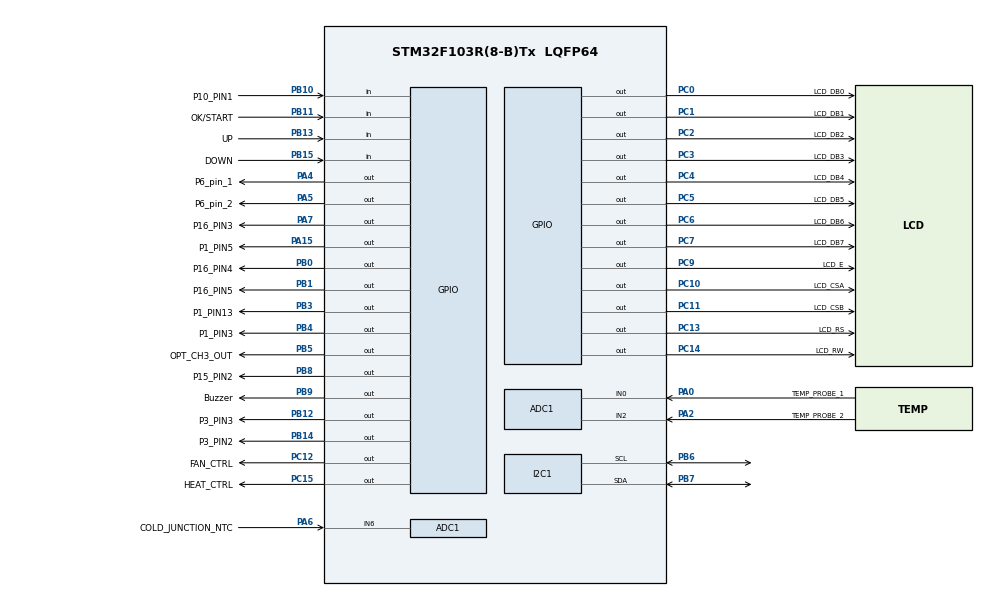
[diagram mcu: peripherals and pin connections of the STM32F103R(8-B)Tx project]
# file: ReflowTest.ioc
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ADC1.Channel-0\#ChannelRegularConversion=ADC_CHANNEL_6
ADC1.NbrOfConversionFlag=1
ADC1.Rank-0\#ChannelRegularConversion=1
ADC1.SamplingTime-0\#ChannelRegularConversion=ADC_SAMPLETIME_1CYCLE_5
ADC1.master=1
Mcu.Family=STM32F1
Mcu.Name=STM32F103R(8-B)Tx
Mcu.Package=LQFP64
NVIC.PriorityGroup=NVIC_PRIORITYGROUP_4
PA0-WKUP.GPIO_Label=TEMP_PROBE_1
PA0-WKUP.Signal=ADCx_IN0
PA10.Signal=USART1_RX
PA13.Mode=Serial_Wire
PA13.Signal=SYS_JTMS-SWDIO
PA14.Mode=Serial_Wire
PA14.Signal=SYS_JTCK-SWCLK
PA15.GPIO_Label=P1_PIN5
PA15.Signal=GPIO_Output
PA2.GPIO_Label=TEMP_PROBE_2
PA2.Signal=ADCx_IN2
PA4.GPIO_Label=P6_pin_1
PA4.Signal=GPIO_Output
PA5.GPIO_Label=P6_pin_2
PA5.Signal=GPIO_Output
PA6.GPIO_Label=COLD_JUNCTION_NTC
PA6.Signal=ADCx_IN6
PA7.GPIO_Label=P16_PIN3
PA7.Signal=GPIO_Output
PA9.Signal=USART1_TX
PB0.GPIO_Label=P16_PIN4
PB0.Signal=GPIO_Output
PB1.GPIO_Label=P16_PIN5
PB1.Signal=GPIO_Output
PB10.GPIO_Label=P10_PIN1
PB10.Signal=GPIO_Input
PB11.GPIO_Label=OK/START
PB11.GPIO_PuPd=GPIO_PULLUP
PB11.Signal=GPIO_Input
PB12.GPIO_Label=P3_PIN3
PB12.Signal=GPIO_Output
PB13.GPIO_Label=UP
PB13.GPIO_PuPd=GPIO_PULLUP
PB13.Signal=GPIO_Input
PB14.GPIO_Label=P3_PIN2
PB14.Signal=GPIO_Output
PB15.GPIO_Label=DOWN
PB15.GPIO_PuPd=GPIO_PULLUP
PB15.Signal=GPIO_Input
PB3.GPIO_Label=P1_PIN13
PB3.Signal=GPIO_Output
PB4.GPIO_Label=P1_PIN3
PB4.Signal=GPIO_Output
PB5.GPIO_Label=OPT_CH3_OUT
PB5.Signal=GPIO_Output
PB6.Mode=I2C
PB6.Signal=I2C1_SCL
PB7.Mode=I2C
PB7.Signal=I2C1_SDA
PB8.GPIO_Label=P15_PIN2
PB8.Signal=GPIO_Output
PB9.GPIO_Label=Buzzer
PB9.Signal=GPIO_Output
PC0.GPIO_Label=LCD_DB0
PC0.Signal=GPIO_Output
PC1.GPIO_Label=LCD_DB1
PC1.Signal=GPIO_Output
PC10.GPIO_Label=LCD_CSA
PC10.Signal=GPIO_Output
PC11.GPIO_Label=LCD_CSB
PC11.Signal=GPIO_Output
PC12.GPIO_Label=FAN_CTRL
PC12.GPIO_PuPd=GPIO_PULLDOWN
PC12.Signal=GPIO_Output
PC13-TAMPER-RTC.GPIO_Label=LCD_RS
PC13-TAMPER-RTC.Signal=GPIO_Output
PC14-OSC32_IN.GPIO_Label=LCD_RW
PC14-OSC32_IN.GPIO_PuPd=GPIO_PULLDOWN
PC14-OSC32_IN.Signal=GPIO_Output
PC15-OSC32_OUT.GPIO_Label=HEAT_CTRL
PC15-OSC32_OUT.GPIO_PuPd=GPIO_PULLDOWN
PC15-OSC32_OUT.Signal=GPIO_Output
PC2.GPIO_Label=LCD_DB2
PC2.Signal=GPIO_Output
PC3.GPIO_Label=LCD_DB3
PC3.Signal=GPIO_Output
PC4.GPIO_Label=LCD_DB4
PC4.Signal=GPIO_Output
PC5.GPIO_Label=LCD_DB5
PC5.Signal=GPIO_Output
PC6.GPIO_Label=LCD_DB6
PC6.Signal=GPIO_Output
PC7.GPIO_Label=LCD_DB7
PC7.Signal=GPIO_Output
PC9.GPIO_Label=LCD_E
PC9.Signal=GPIO_Output
PD0-OSC_IN.Mode=HSE-External-Oscillator
PD0-OSC_IN.Signal=RCC_OSC_IN
PD1-OSC_OUT.Mode=HSE-External-Oscillator
PD1-OSC_OUT.Signal=RCC_OSC_OUT
ProjectManager.HeapSize=0x200
ProjectManager.StackSize=0x400
ProjectManager.TargetToolchain=STM32CubeIDE
RCC.APB1Freq_Value=8000000
RCC.APB2Freq_Value=8000000
RCC.SYSCLKSource=RCC_SYSCLKSOURCE_HSE
SH.ADCx_IN0.0=ADC1_IN0,IN0
SH.ADCx_IN2.0=ADC1_IN2,IN2
SH.ADCx_IN6.0=ADC1_IN6,IN6
board=custom

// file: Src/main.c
/* USER CODE BEGIN Header */
/**
  ******************************************************************************
  * @file           : main.c
  * @brief          : Main program body
  ******************************************************************************
  * @attention
  *
  * Copyright (c) 2026 STMicroelectronics.
  * All rights reserved.
  *
  * This software is licensed under terms that can be found in the LICENSE file
  * in the root directory of this software component.
  * If no LICENSE file comes with this software, it is provided AS-IS.
  *
  ******************************************************************************
  */
/* USER CODE END Header */
#include "main.h"
#include "app.h"

ADC_HandleTypeDef hadc1;
I2C_HandleTypeDef hi2c1;

void SystemClock_Config(void);
static void MX_GPIO_Init(void);
static void MX_I2C1_Init(void);
static void MX_ADC1_Init(void);

int main(void)
{
  HAL_Init();
  SystemClock_Config();
  MX_GPIO_Init();
  MX_I2C1_Init();
  MX_ADC1_Init();

  /* USER CODE BEGIN 2 */
  app_init();
  /* USER CODE END 2 */

  while (1)
  {
    /* USER CODE BEGIN 3 */
    uint32_t now_ms = HAL_GetTick();
    app_task(now_ms);
    HAL_Delay(10U);
    /* USER CODE END 3 */
  }
}

void SystemClock_Config(void)
{
  RCC_OscInitTypeDef RCC_OscInitStruct = {0};
  RCC_ClkInitTypeDef RCC_ClkInitStruct = {0};
  RCC_PeriphCLKInitTypeDef PeriphClkInit = {0};

  RCC_OscInitStruct.OscillatorType = RCC_OSCILLATORTYPE_HSE;
  RCC_OscInitStruct.HSEState = RCC_HSE_ON;
  RCC_OscInitStruct.PLL.PLLState = RCC_PLL_NONE;
  if (HAL_RCC_OscConfig(&RCC_OscInitStruct) != HAL_OK)
  {
    Error_Handler();
  }

  RCC_ClkInitStruct.ClockType = RCC_CLOCKTYPE_HCLK|RCC_CLOCKTYPE_SYSCLK
                              |RCC_CLOCKTYPE_PCLK1|RCC_CLOCKTYPE_PCLK2;
  RCC_ClkInitStruct.SYSCLKSource = RCC_SYSCLKSOURCE_HSE;
  RCC_ClkInitStruct.AHBCLKDivider = RCC_SYSCLK_DIV1;
  RCC_ClkInitStruct.APB1CLKDivider = RCC_HCLK_DIV1;
  RCC_ClkInitStruct.APB2CLKDivider = RCC_HCLK_DIV1;

  if (HAL_RCC_ClockConfig(&RCC_ClkInitStruct, FLASH_LATENCY_0) != HAL_OK)
  {
    Error_Handler();
  }
  PeriphClkInit.PeriphClockSelection = RCC_PERIPHCLK_ADC;
  PeriphClkInit.AdcClockSelection = RCC_ADCPCLK2_DIV2;
  if (HAL_RCCEx_PeriphCLKConfig(&PeriphClkInit) != HAL_OK)
  {
    Error_Handler();
  }
}

static void MX_ADC1_Init(void)
{
  ADC_ChannelConfTypeDef sConfig = {0};

  hadc1.Instance = ADC1;
  hadc1.Init.ScanConvMode = ADC_SCAN_DISABLE;
  hadc1.Init.ContinuousConvMode = DISABLE;
  hadc1.Init.DiscontinuousConvMode = DISABLE;
  hadc1.Init.ExternalTrigConv = ADC_SOFTWARE_START;
  hadc1.Init.DataAlign = ADC_DATAALIGN_RIGHT;
  hadc1.Init.NbrOfConversion = 1;
  if (HAL_ADC_Init(&hadc1) != HAL_OK)
  {
    Error_Handler();
  }

  sConfig.Channel = ADC_CHANNEL_6;
  sConfig.Rank = ADC_REGULAR_RANK_1;
  sConfig.SamplingTime = ADC_SAMPLETIME_239CYCLES_5;
  if (HAL_ADC_ConfigChannel(&hadc1, &sConfig) != HAL_OK)
  {
    Error_Handler();
  }
}

static void MX_I2C1_Init(void)
{
  hi2c1.Instance = I2C1;
  hi2c1.Init.ClockSpeed = 100000;
  hi2c1.Init.DutyCycle = I2C_DUTYCYCLE_2;
  hi2c1.Init.OwnAddress1 = 0;
  hi2c1.Init.AddressingMode = I2C_ADDRESSINGMODE_7BIT;
  hi2c1.Init.DualAddressMode = I2C_DUALADDRESS_DISABLE;
  hi2c1.Init.OwnAddress2 = 0;
  hi2c1.Init.GeneralCallMode = I2C_GENERALCALL_DISABLE;
  hi2c1.Init.NoStretchMode = I2C_NOSTRETCH_DISABLE;
  if (HAL_I2C_Init(&hi2c1) != HAL_OK)
  {
    Error_Handler();
  }
}

static void MX_GPIO_Init(void)
{
  GPIO_InitTypeDef GPIO_InitStruct = {0};

  __HAL_RCC_GPIOC_CLK_ENABLE();
  __HAL_RCC_GPIOD_CLK_ENABLE();
  __HAL_RCC_GPIOA_CLK_ENABLE();
  __HAL_RCC_GPIOB_CLK_ENABLE();

  HAL_GPIO_WritePin(GPIOC, LCD_RS_Pin|LCD_RW_Pin|HEAT_CTRL_Pin|LCD_DB0_Pin
                          |LCD_DB1_Pin|LCD_DB2_Pin|LCD_DB3_Pin|LCD_DB4_Pin
                          |LCD_DB5_Pin|LCD_DB6_Pin|LCD_DB7_Pin|LCD_E_Pin
                          |LCD_CSA_Pin|LCD_CSB_Pin|FAN_CTRL_Pin, GPIO_PIN_RESET);

  HAL_GPIO_WritePin(GPIOA, P6_pin_1_Pin|P6_pin_2_Pin|P16_PIN3_Pin|P1_PIN5_Pin, GPIO_PIN_RESET);

  HAL_GPIO_WritePin(GPIOB, P16_PIN4_Pin|P16_PIN5_Pin|P3_PIN3_Pin|P3_PIN2_Pin
                          |P1_PIN13_Pin|P1_PIN3_Pin|OPT_CH3_OUT_Pin|P15_PIN2_Pin
                          |Buzzer_Pin, GPIO_PIN_RESET);

  GPIO_InitStruct.Pin = LCD_RS_Pin|LCD_DB0_Pin|LCD_DB1_Pin|LCD_DB2_Pin
                          |LCD_DB3_Pin|LCD_DB4_Pin|LCD_DB5_Pin|LCD_DB6_Pin
                          |LCD_DB7_Pin|LCD_E_Pin|LCD_CSA_Pin|LCD_CSB_Pin;
  GPIO_InitStruct.Mode = GPIO_MODE_OUTPUT_PP;
  GPIO_InitStruct.Pull = GPIO_NOPULL;
  GPIO_InitStruct.Speed = GPIO_SPEED_FREQ_LOW;
  HAL_GPIO_Init(GPIOC, &GPIO_InitStruct);

  GPIO_InitStruct.Pin = LCD_RW_Pin|HEAT_CTRL_Pin|FAN_CTRL_Pin;
  GPIO_InitStruct.Mode = GPIO_MODE_OUTPUT_PP;
  GPIO_InitStruct.Pull = GPIO_PULLDOWN;
  GPIO_InitStruct.Speed = GPIO_SPEED_FREQ_LOW;
  HAL_GPIO_Init(GPIOC, &GPIO_InitStruct);

  GPIO_InitStruct.Pin = P6_pin_1_Pin|P6_pin_2_Pin|P16_PIN3_Pin|P1_PIN5_Pin;
  GPIO_InitStruct.Mode = GPIO_MODE_OUTPUT_PP;
  GPIO_InitStruct.Pull = GPIO_NOPULL;
  GPIO_InitStruct.Speed = GPIO_SPEED_FREQ_LOW;
  HAL_GPIO_Init(GPIOA, &GPIO_InitStruct);

  GPIO_InitStruct.Pin = P16_PIN4_Pin|P16_PIN5_Pin|P3_PIN3_Pin|P3_PIN2_Pin
                          |P1_PIN13_Pin|P1_PIN3_Pin|OPT_CH3_OUT_Pin|P15_PIN2_Pin
                          |Buzzer_Pin;
  GPIO_InitStruct.Mode = GPIO_MODE_OUTPUT_PP;
  GPIO_InitStruct.Pull = GPIO_NOPULL;
  GPIO_InitStruct.Speed = GPIO_SPEED_FREQ_LOW;
  HAL_GPIO_Init(GPIOB, &GPIO_InitStruct);

  GPIO_InitStruct.Pin = P10_PIN1_Pin;
  GPIO_InitStruct.Mode = GPIO_MODE_INPUT;
  GPIO_InitStruct.Pull = GPIO_NOPULL;
  HAL_GPIO_Init(P10_PIN1_GPIO_Port, &GPIO_InitStruct);

  GPIO_InitStruct.Pin = OK_START_Pin|UP_Pin|DOWN_Pin;
  GPIO_InitStruct.Mode = GPIO_MODE_INPUT;
  GPIO_InitStruct.Pull = GPIO_PULLUP;
  HAL_GPIO_Init(GPIOB, &GPIO_InitStruct);

  GPIO_InitStruct.Pin = GPIO_PIN_9;
  GPIO_InitStruct.Mode = GPIO_MODE_AF_PP;
  GPIO_InitStruct.Speed = GPIO_SPEED_FREQ_HIGH;
  HAL_GPIO_Init(GPIOA, &GPIO_InitStruct);

  GPIO_InitStruct.Pin = GPIO_PIN_10;
  GPIO_InitStruct.Mode = GPIO_MODE_INPUT;
  GPIO_InitStruct.Pull = GPIO_NOPULL;
  HAL_GPIO_Init(GPIOA, &GPIO_InitStruct);
}

void Error_Handler(void)
{
  __disable_irq();
  while (1)
  {
  }
}
